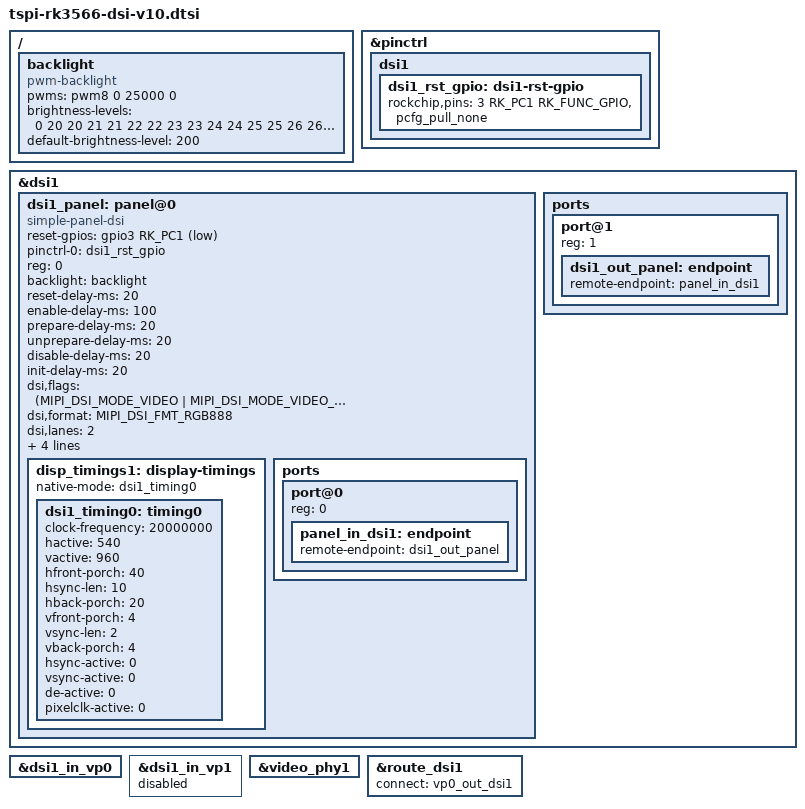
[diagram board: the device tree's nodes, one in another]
/********************************************************************
 * SPDX-License-Identifier: (GPL-2.0+ OR MIT)
 * 
 * Copyright (c) 2023 Rockchip Electronics Co., Ltd.
 * Copyright (c) 2026 LCKFB <lckfb@sz-jlc.com>
 *********************************************************************
 * Wiki-(Chinese)：https://wiki.lckfb.com/
 * Wiki-(English)：https://wiki.lckfb.com/en/
 *********************************************************************/
/ {
	backlight: backlight {
		compatible = "pwm-backlight";
		pwms = <&pwm8 0 25000 0>;
		brightness-levels = <
			  0  20  20  21  21  22  22  23
			 23  24  24  25  25  26  26  27
			 27  28  28  29  29  30  30  31
			 31  32  32  33  33  34  34  35
			 35  36  36  37  37  38  38  39
			 40  41  42  43  44  45  46  47
			 48  49  50  51  52  53  54  55
			 56  57  58  59  60  61  62  63
			 64  65  66  67  68  69  70  71
			 72  73  74  75  76  77  78  79
			 80  81  82  83  84  85  86  87
			 88  89  90  91  92  93  94  95
			 96  97  98  99 100 101 102 103
			104 105 106 107 108 109 110 111
			112 113 114 115 116 117 118 119
			120 121 122 123 124 125 126 127
			128 129 130 131 132 133 134 135
			136 137 138 139 140 141 142 143
			144 145 146 147 148 149 150 151
			152 153 154 155 156 157 158 159
			160 161 162 163 164 165 166 167
			168 169 170 171 172 173 174 175
			176 177 178 179 180 181 182 183
			184 185 186 187 188 189 190 191
			192 193 194 195 196 197 198 199
			200 201 202 203 204 205 206 207
			208 209 210 211 212 213 214 215
			216 217 218 219 220 221 222 223
			224 225 226 227 228 229 230 231
			232 233 234 235 236 237 238 239
			240 241 242 243 244 245 246 247
			248 249 250 251 252 253 254 255
		>;
		default-brightness-level = <200>;
	};
};


&pinctrl {
	dsi1 {
		dsi1_rst_gpio: dsi1-rst-gpio {
			rockchip,pins = <3 RK_PC1 RK_FUNC_GPIO &pcfg_pull_none>;
		};
	};
};

/*
 * video_phy1 needs to be enabled
 * when dsi1 is enabled
 */
&dsi1 {
	status = "okay";
};

&dsi1_in_vp0 {
	status = "okay";
	// status = "disabled";
};

&dsi1_in_vp1 {
	status = "disabled";
	// status = "okay";
};

&video_phy1 {
	status = "okay";
};

&route_dsi1 {
	status = "okay";
	connect = <&vp0_out_dsi1>;
};


// 5 inch 540x960
&dsi1 {
        status = "okay";
    
        dsi1_panel: panel@0 {
			status = "okay";
			compatible = "simple-panel-dsi";
			reset-gpios = <&gpio3 RK_PC1 GPIO_ACTIVE_LOW>;
			pinctrl-names = "default";
			pinctrl-0 = <&dsi1_rst_gpio>;
			reg = <0>;
			backlight = <&backlight>;
			reset-delay-ms = <20>;
			enable-delay-ms = <100>;
			prepare-delay-ms = <20>;
			unprepare-delay-ms = <20>;
			disable-delay-ms = <20>;
			init-delay-ms = <20>;
			dsi,flags = <(MIPI_DSI_MODE_VIDEO | MIPI_DSI_MODE_VIDEO_BURST |
				MIPI_DSI_MODE_LPM | MIPI_DSI_MODE_NO_EOT_PACKET)>;
			dsi,format = <MIPI_DSI_FMT_RGB888>;
			dsi,lanes  = <2>;
			panel-init-sequence = [
				15 00 02 00 00
				39 00 04 FF 96 08 01
				15 00 02 00 80
				39 00 03 FF 96 08
				15 00 02 00 00
				15 00 02 A0 00
				15 00 02 00 80
				39 00 06 B3 00 00 20 00 00
				15 00 02 00 C0
				15 00 02 B3 09
				15 00 02 00 80
				39 00 0A C0 00 48 00 0F 11 00 48 0F 11
				15 00 02 00 92
				39 00 05 C0 00 10 00 13
				15 00 02 00 A2
				39 00 04 C0 0C 05 02
				15 00 02 00 B3
				39 00 03 C0 00 50
				15 00 02 00 81
				15 00 02 C1 66
				15 00 02 00 80
				39 00 03 C4 00 84
				15 00 02 00 A0
				39 00 09 C4 33 09 90 2B 33 09 90 54
				15 00 02 00 80
				39 00 05 C5 08 00 A0 11
				15 00 02 00 90
				39 00 08 C5 D6 12 01 79 33 33 34
				15 00 02 00 A0
				39 00 08 C5 D6 13 00 79 33 33 34
				15 00 02 00 00
				39 00 03 D8 6F 6F
				15 00 02 00 00
				15 00 02 D9 24
				15 00 02 00 00
				39 00 11 E1 01 0D 14 0D 06 12 0C 0C 02 06 09 07 0E 12 0E 01
				15 00 02 00 00
				39 00 11 E2 01 0E 15 0D 06 13 0C 0C 01 05 08 07 0D 12 0E 01
				15 00 02 00 B0
				39 00 03 C5 04 A8
				15 00 02 00 80
				15 00 02 C6 64
				15 00 02 00 B0
				39 00 06 C6 03 10 00 1F 12
				15 00 02 00 B7
				15 00 02 B0 10
				15 00 02 00 C0
				15 00 02 B0 55
				15 00 02 00 B1
				15 00 02 B0 03
				15 00 02 00 80
				39 00 0B CB 05 00 00 00 00 05 00 00 00 00
				15 00 02 00 90
				39 00 10 CB 55 55 00 00 00 00 00 00 00 00 00 00 00 00 00
				15 00 02 00 A0
				39 00 10 CB 00 00 00 00 00 55 55 00 00 00 00 00 00 00 00
				15 00 02 00 B0
				39 00 0B CB 00 00 00 00 00 00 00 00 00 00
				15 00 02 00 C0
				39 00 10 CB 55 55 00 00 00 04 00 04 00 04 00 04 04 04 00
				15 00 02 00 D0
				39 00 10 CB 04 00 00 00 00 55 55 00 00 00 04 00 04 00 04
				15 00 02 00 E0
				39 00 0B CB 00 04 04 04 00 04 00 00 00 00
				15 00 02 00 F0
				39 00 0B CB 0F 00 CC 00 00 0F 00 CC C3 00
				15 00 02 00 80
				39 00 0B CC 25 26 00 00 00 0C 00 0A 00 10
				15 00 02 00 90
				39 00 10 CC 00 0E 02 04 00 06 00 00 00 00 25 26 00 00 00
				15 00 02 00 A0
				39 00 10 CC 0B 00 09 00 0F 00 0D 01 03 00 05 00 00 00 00
				15 00 02 00 B0
				39 00 0B CC 26 25 00 00 00 0D 00 0F 00 09
				15 00 02 00 C0
				39 00 10 CC 00 0B 03 01 00 05 00 00 00 00 26 25 00 00 00
				15 00 02 00 D0
				39 00 10 CC 0E 00 10 00 0A 00 0C 04 02 00 06 00 00 00 00
				15 00 02 00 80
				39 00 0D CE 8A 03 28 89 03 28 88 03 28 87 03 28
				15 00 02 00 90
				39 00 10 CE 38 0F 28 38 0E 28 00 00 00 00 00 00 00 00 00
				15 00 02 00 A0
				39 00 0F CE 38 06 03 C1 00 28 00 38 05 03 C2 00 28 00
				15 00 02 00 B0
				39 00 0F CE 38 04 03 C3 00 28 00 38 03 03 C4 00 28 00
				15 00 02 00 C0
				39 00 0F CE 38 02 03 C5 00 28 00 38 01 03 C6 00 28 00
				15 00 02 00 D0
				39 00 0F CE 38 00 03 C7 00 28 00 30 00 03 C8 00 28 00
				15 00 02 00 80
				39 00 0F CF F0 00 00 10 00 00 00 F0 00 00 10 00 00 00
				15 00 02 00 90
				39 00 0F CF F0 00 00 10 00 00 00 F0 00 00 10 00 00 00
				15 00 02 00 A0
				39 00 0F CF F0 00 00 10 00 00 00 F0 00 00 10 00 00 00
				15 00 02 00 B0
				39 00 0F CF F0 00 00 10 00 00 00 F0 00 00 10 00 00 00
				15 00 02 00 C0
				39 00 0B CF 01 01 20 20 00 00 02 01 00 00
				15 00 02 00 00
				39 00 04 FF FF FF FF
				05 00 01 11
				05 DC 01 29
			];

			panel-exit-sequence = [
				05 00 01 28
				05 00 01 10
			];

                disp_timings1: display-timings {
                        native-mode = <&dsi1_timing0>;
                        dsi1_timing0: timing0 {
                                clock-frequency = <20000000>;//驱动手册上为35500000，如果撕裂，尝试20000000;
								hactive = <540>;
								vactive = <960>;
								hfront-porch = <40>;
								hsync-len = <10>;
								hback-porch = <20>;
								vfront-porch = <4>;
								vsync-len = <2>;
								vback-porch = <4>;
                                hsync-active = <0>;
                                vsync-active = <0>;
                                de-active = <0>;
                                pixelclk-active = <0>;
                        };
                };
        ports {
                        #address-cells = <1>;
                        #size-cells = <0>;
                        port@0 {
                                reg = <0>;
                                panel_in_dsi1: endpoint {
                                        remote-endpoint = <&dsi1_out_panel>;
                                };
                        };
                };
        };
        ports {
                #address-cells = <1>;
                #size-cells = <0>;
                port@1 {
                        reg = <1>;
                        dsi1_out_panel: endpoint {
                                remote-endpoint = <&panel_in_dsi1>;
                        };
                };
        };
};


